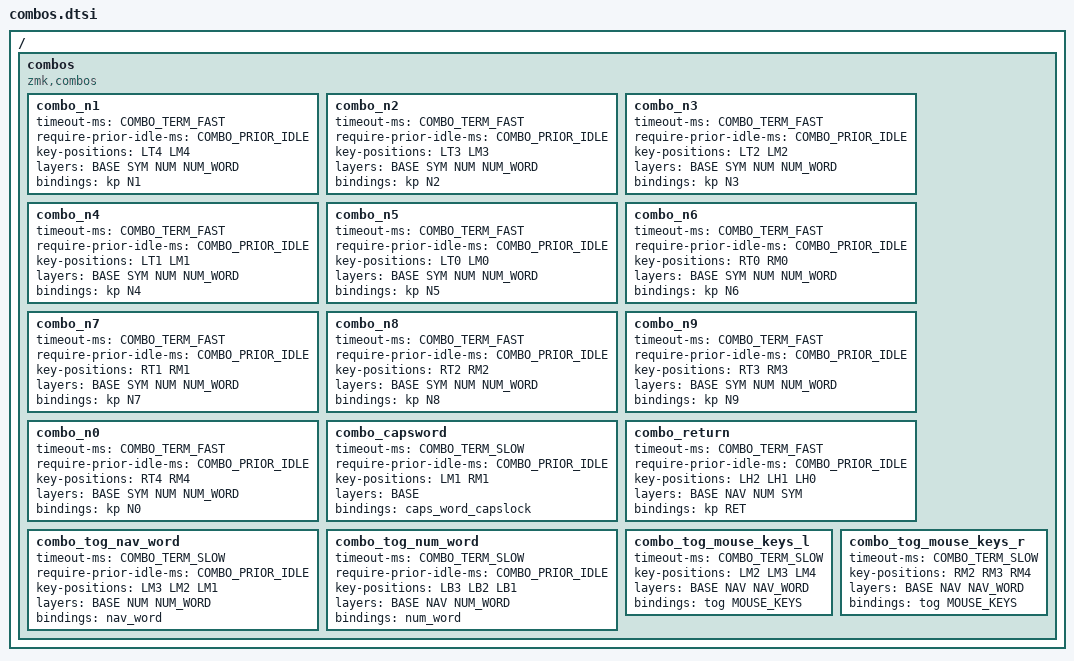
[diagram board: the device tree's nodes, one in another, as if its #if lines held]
#define COMBO_TERM_FAST 35
#define COMBO_TERM_SLOW 40
#define COMBO_TERM_SLOWER 50
#define COMBO_PRIOR_IDLE 100

// #define COMBO_TERM_FAST 18
// #define COMBO_TERM_SLOW 30

#define COMBO_IDLE_FAST 150
#define COMBO_IDLE_SLOW 50

ZMK_COMBO(esc,    &kp ESC,       LT3 LT2,     BASE NAV_WORD NAV NUM, COMBO_TERM_FAST, COMBO_IDLE_FAST)
ZMK_COMBO(cancel, &kp K_CANCEL,  LT4 LT3,     BASE NAV_WORD NAV NUM, COMBO_TERM_FAST, COMBO_IDLE_FAST)
ZMK_COMBO(ret,    &kp RETURN,    RM3 RM2,     BASE NAV NUM, COMBO_TERM_FAST, COMBO_IDLE_FAST)
// ZMK_COMBO(mouse, &smart_mouse, LT3 LT1,     DEF NAV NUM, COMBO_TERM_FAST, COMBO_IDLE_FAST)

// Combos overlapping HRMs are set up as hold-taps themselves to allow for instantaneous
// chording of mods. Custom hold-tap instances can be bootstrapped on the go using the
// 8-argument version of ZMK_COMBO defined in base.keymap.
ZMK_COMBO(tab,   &hm_l LS(LALT)TAB, LM3 LM2, BASE NAV NUM, COMBO_TERM_FAST, COMBO_IDLE_FAST)
// ZMK_COMBO(ldr,   &leader,      LM2 LM1,     BASE NAV NUM, COMBO_TERM_FAST, COMBO_IDLE_FAST, LS(LCTRL),    KEYS_R)
// ZMK_COMBO(ldrsh, &leader_sft,  LM3 LM2 LM1, BASE NAV NUM, COMBO_TERM_FAST, COMBO_IDLE_FAST, LS(LC(LALT)), KEYS_R)

ZMK_COMBO(cut,   &kp LC(X),    LB3 LB1,     BASE NAV NUM, COMBO_TERM_FAST, COMBO_IDLE_FAST)
ZMK_COMBO(copy,  &kp LC(INS),  LB3 LB2,     BASE NAV NUM, COMBO_TERM_FAST, COMBO_IDLE_FAST)
ZMK_COMBO(paste, &kp LS(INS),  LB2 LB1,     BASE NAV NUM, COMBO_TERM_FAST, COMBO_IDLE_FAST)

/* Horizontal combos - right hand */
ZMK_COMBO(bspc,  &kp BSPC,     RT1 RT2,     BASE NAV NUM, COMBO_TERM_SLOWER,  COMBO_IDLE_FAST)
ZMK_COMBO(del,   &kp DEL,      RT2 RT3,     BASE NAV NUM, COMBO_TERM_FAST,    COMBO_IDLE_FAST)

// ZMK_COMBO(lpar,  &lpar_lt,     RM1 RM2,     BASE     NUM, COMBO_TERM_FAST, COMBO_IDLE_FAST, RS(LCTRL),    KEYS_L)
// ZMK_COMBO(rpar,  &rpar_gt,     RM2 RM3,     BASE     NUM, COMBO_TERM_FAST, COMBO_IDLE_FAST, RS(LALT),     KEYS_L)
// ZMK_COMBO(lt,    &kp LT,       RM1 RM2,         NAV    , COMBO_TERM_FAST, COMBO_IDLE_FAST)
// ZMK_COMBO(gt,    &kp GT,       RM2 RM3,         NAV    , COMBO_TERM_FAST, COMBO_IDLE_FAST)
// mine
// ZMK_COMBO(lpar,  &kp LPAR,     RM1 RM2,     BASE     NUM, COMBO_TERM_FAST, COMBO_IDLE_FAST, RS(LCTRL),    KEYS_L)
// ZMK_COMBO(rpar,  &kp RPAR,     RM2 RM3,     BASE     NUM, COMBO_TERM_FAST, COMBO_IDLE_FAST, RS(LALT),     KEYS_L)

// ZMK_COMBO(lbkt,  &kp LBKT,     RB1 RB2,     BASE     NUM, COMBO_TERM_FAST, COMBO_IDLE_FAST)
// ZMK_COMBO(rbkt,  &kp RBKT,     RB2 RB3,     BASE     NUM, COMBO_TERM_FAST, COMBO_IDLE_FAST)
// ZMK_COMBO(lbrc,  &kp LBRC,     RB1 RB2,         NAV    , COMBO_TERM_FAST, COMBO_IDLE_FAST)
// ZMK_COMBO(rbrc,  &kp RBRC,     RB2 RB3,         NAV    , COMBO_TERM_FAST, COMBO_IDLE_FAST)

// ZMK_COMBO(under, &kp UNDER,    RM0 RB0,     BASE NAV NUM, COMBO_TERM_SLOW, COMBO_IDLE_SLOW)
// ZMK_COMBO(minus, &kp MINUS,    RM1 RB1,     BASE NAV NUM, COMBO_TERM_SLOW, COMBO_IDLE_SLOW)

/ {
  combos {
    compatible = "zmk,combos";

    // combo_bracket_round_l {
    //   timeout-ms = <COMBO_TERM_FAST>;
    //   require-prior-idle-ms = <COMBO_PRIOR_IDLE>;
    //   key-positions = <LM2 LM1>;
    //   layers = <BASE BASE_QWERTY SYM NUM NUM_WORD>;
    //   bindings = <&kp LPAR>;
    // };

    // combo_bracket_round_r {
    //   timeout-ms = <COMBO_TERM_FAST>;
    //   require-prior-idle-ms = <COMBO_PRIOR_IDLE>;
    //   key-positions = <RM1 RM2>;
    //   layers = <BASE BASE_QWERTY SYM NUM NUM_WORD>;
    //   bindings = <&kp RPAR>;
    // };

    // combo_bracket_square_l {
    //   timeout-ms = <COMBO_TERM_SLOW>;
    //   require-prior-idle-ms = <COMBO_PRIOR_IDLE>;
    //   key-positions = <LB2 LB1>;
    //   layers = <BASE BASE_QWERTY SYM NUM NUM_WORD>;
    //   bindings = <&kp LBKT>;
    // };

    // combo_bracket_square_r {
    //   timeout-ms = <COMBO_TERM_SLOW>;
    //   require-prior-idle-ms = <COMBO_PRIOR_IDLE>;
    //   key-positions = <RB1 RB2>;
    //   layers = <BASE BASE_QWERTY SYM NUM NUM_WORD>;
    //   bindings = <&kp RBKT>;
    // };

    // combo_bracket_curly_l {
    //   timeout-ms = <COMBO_TERM_SLOW>;
    //   require-prior-idle-ms = <COMBO_PRIOR_IDLE>;
    //   key-positions = <LT2 LT1>;
    //   layers = <BASE BASE_QWERTY SYM NUM NUM_WORD>;
    //   bindings = <&kp LBRC>;
    // };

    // combo_bracket_curly_r {
    //   timeout-ms = <COMBO_TERM_SLOW>;
    //   require-prior-idle-ms = <COMBO_PRIOR_IDLE>;
    //   key-positions = <RT2 RT1>;
    //   layers = <BASE BASE_QWERTY SYM NUM NUM_WORD>;
    //   bindings = <&kp RBRC>;
    // };

    // combo_bracket_angled_l {
    //   timeout-ms = <COMBO_TERM_SLOW>;
    //   require-prior-idle-ms = <COMBO_PRIOR_IDLE>;
    //   key-positions = <LM3 LM2>;
    //   layers = <BASE BASE_QWERTY SYM NUM NUM_WORD>;
    //   bindings = <&kp LT>;
    // };

    // combo_bracket_angled_r {
    //   timeout-ms = <COMBO_TERM_SLOW>;
    //   require-prior-idle-ms = <COMBO_PRIOR_IDLE>;
    //   key-positions = <RM3 RM2>;
    //   layers = <BASE BASE_QWERTY SYM NUM NUM_WORD>;
    //   bindings = <&kp GT>;
    // };

    // Mine
    combo_n1 {
      timeout-ms = <COMBO_TERM_FAST>;
      require-prior-idle-ms = <COMBO_PRIOR_IDLE>;
      key-positions = <LT4 LM4>;
      layers = <BASE SYM NUM NUM_WORD>;
      // layers = <BASE NAV SYM ADJ>;
      bindings = <&kp N1>;
    };

    combo_n2 {
      timeout-ms = <COMBO_TERM_FAST>;
      require-prior-idle-ms = <COMBO_PRIOR_IDLE>;
      key-positions = <LT3 LM3>;
      layers = <BASE SYM NUM NUM_WORD>;
      // layers = <BASE NAV SYM ADJ>;
      bindings = <&kp N2>;
    };

    combo_n3 {
      timeout-ms = <COMBO_TERM_FAST>;
      require-prior-idle-ms = <COMBO_PRIOR_IDLE>;
      key-positions = <LT2 LM2>;
      layers = <BASE SYM NUM NUM_WORD>;
      // layers = <BASE NAV SYM ADJ>;
      bindings = <&kp N3>;
    };

    combo_n4 {
      timeout-ms = <COMBO_TERM_FAST>;
      require-prior-idle-ms = <COMBO_PRIOR_IDLE>;
      key-positions = <LT1 LM1>;
      layers = <BASE SYM NUM NUM_WORD>;
      // layers = <BASE NAV SYM ADJ>;
      bindings = <&kp N4>;
    };

    combo_n5 {
      timeout-ms = <COMBO_TERM_FAST>;
      require-prior-idle-ms = <COMBO_PRIOR_IDLE>;
      key-positions = <LT0 LM0>;
      layers = <BASE SYM NUM NUM_WORD>;
      // layers = <BASE NAV SYM ADJ>;
      bindings = <&kp N5>;
    };

    combo_n6 {
      timeout-ms = <COMBO_TERM_FAST>;
      require-prior-idle-ms = <COMBO_PRIOR_IDLE>;
      key-positions = <RT0 RM0>;
      layers = <BASE SYM NUM NUM_WORD>;
      // layers = <BASE NAV SYM ADJ>;
      bindings = <&kp N6>;
    };

    combo_n7 {
      timeout-ms = <COMBO_TERM_FAST>;
      require-prior-idle-ms = <COMBO_PRIOR_IDLE>;
      key-positions = <RT1 RM1>;
      layers = <BASE SYM NUM NUM_WORD>;
      // layers = <BASE NAV SYM ADJ>;
      bindings = <&kp N7>;
    };

    combo_n8 {
      timeout-ms = <COMBO_TERM_FAST>;
      require-prior-idle-ms = <COMBO_PRIOR_IDLE>;
      key-positions = <RT2 RM2>;
      layers = <BASE SYM NUM NUM_WORD>;
      // layers = <BASE NAV SYM ADJ>;
      bindings = <&kp N8>;
    };

    combo_n9 {
      timeout-ms = <COMBO_TERM_FAST>;
      require-prior-idle-ms = <COMBO_PRIOR_IDLE>;
      key-positions = <RT3 RM3>;
      layers = <BASE SYM NUM NUM_WORD>;
      // layers = <BASE NAV SYM ADJ>;
      bindings = <&kp N9>;
    };

    combo_n0 {
      timeout-ms = <COMBO_TERM_FAST>;
      require-prior-idle-ms = <COMBO_PRIOR_IDLE>;
      key-positions = <RT4 RM4>;
      layers = <BASE SYM NUM NUM_WORD>;
      // layers = <BASE NAV SYM ADJ>;
      bindings = <&kp N0>;
    };
    // End mine

    // combo_bracket_v_round_l {
    //   timeout-ms = <COMBO_TERM_FAST>;
    //   require-prior-idle-ms = <COMBO_PRIOR_IDLE>;
    //   key-positions = <LT1 LM1>;
    //   layers = <BASE SYM NUM NUM_WORD>;
    //   // layers = <BASE NAV SYM ADJ>;
    //   bindings = <&kp LPAR>;
    // };
    //
    // combo_bracket_v_round_r {
    //   timeout-ms = <COMBO_TERM_FAST>;
    //   require-prior-idle-ms = <COMBO_PRIOR_IDLE>;
    //   key-positions = <RT1 RM1>;
    //   // layers = <BASE BASE_QWERTY SYM NUM NUM_WORD>;
    //   // layers = <BASE NAV SYM ADJ>;
    //   layers = <BASE SYM NUM NUM_WORD>;
    //   bindings = <&kp RPAR>;
    // };
    //
    // combo_bracket_v_square_l {
    //   timeout-ms = <COMBO_TERM_SLOW>;
    //   require-prior-idle-ms = <COMBO_PRIOR_IDLE>;
    //   key-positions = <LT2 LM2>;
    //   // layers = <BASE BASE_QWERTY SYM NUM NUM_WORD>;
    //   layers = <BASE SYM NUM NUM_WORD>;
    //   // layers = <BASE NAV SYM ADJ>;
    //   bindings = <&kp LBKT>;
    // };
    //
    // combo_bracket_v_square_r {
    //   timeout-ms = <COMBO_TERM_SLOW>;
    //   require-prior-idle-ms = <COMBO_PRIOR_IDLE>;
    //   key-positions = <RT2 RM2>;
    //   // layers = <BASE BASE_QWERTY SYM NUM NUM_WORD>;
    //   layers = <BASE SYM NUM NUM_WORD>;
    //   // layers = <BASE NAV SYM ADJ>;
    //   bindings = <&kp RBKT>;
    // };
    //
    // combo_bracket_v_curly_l {
    //   timeout-ms = <COMBO_TERM_SLOW>;
    //   require-prior-idle-ms = <COMBO_PRIOR_IDLE>;
    //   key-positions = <LT3 LM3>;
    //   // layers = <BASE BASE_QWERTY SYM NUM NUM_WORD>;
    //   layers = <BASE SYM NUM NUM_WORD>;
    //   // layers = <BASE NAV SYM ADJ>;
    //   bindings = <&kp LBRC>;
    // };
    //
    // combo_bracket_v_curly_r {
    //   timeout-ms = <COMBO_TERM_SLOW>;
    //   require-prior-idle-ms = <COMBO_PRIOR_IDLE>;
    //   key-positions = <RT3 RM3>;
    //   // layers = <BASE BASE_QWERTY SYM NUM NUM_WORD>;
    //   layers = <BASE SYM NUM NUM_WORD>;
    //   // layers = <BASE NAV SYM ADJ>;
    //   bindings = <&kp RBRC>;
    // };
    //
    // combo_bracket_v_angled_l {
    //   timeout-ms = <COMBO_TERM_SLOW>;
    //   require-prior-idle-ms = <COMBO_PRIOR_IDLE>;
    //   key-positions = <LM1 LB1>;
    //   // layers = <BASE BASE_QWERTY SYM NUM NUM_WORD>;
    //   layers = <BASE SYM NUM NUM_WORD>;
    //   // layers = <BASE NAV SYM ADJ>;
    //   bindings = <&kp LT>;
    // };
    //
    // combo_bracket_v_angled_r {
    //   timeout-ms = <COMBO_TERM_SLOW>;
    //   require-prior-idle-ms = <COMBO_PRIOR_IDLE>;
    //   key-positions = <RM1 RB1>;
    //   // layers = <BASE BASE_QWERTY SYM NUM NUM_WORD>;
    //   layers = <BASE SYM NUM NUM_WORD>;
    //   // layers = <BASE NAV SYM ADJ>;
    //   bindings = <&kp GT>;
    // };

    combo_capsword {
      timeout-ms = <COMBO_TERM_SLOW>;
      require-prior-idle-ms = <COMBO_PRIOR_IDLE>;
      key-positions = <LM1 RM1>;
      // layers = <BASE BASE_QWERTY>;
      layers = <BASE>;
      // layers = <BASE NAV SYM ADJ>;

#ifdef HAS_CAPSLOCK
      bindings = <&caps_word_capslock >;
#else
      bindings = <&caps_word>;
#endif
    };

    combo_return {
      timeout-ms = <COMBO_TERM_FAST>;
      require-prior-idle-ms = <COMBO_PRIOR_IDLE>;
      key-positions = <LH2 LH1 LH0>;
      // layers = <BASE BASE_QWERTY NAV NUM SYM>;
      layers = <BASE NAV NUM SYM>;
      // layers = <BASE NAV SYM ADJ>;
      bindings = <&kp RET>;
    };

    // combo_bspc {
    //   timeout-ms = <COMBO_TERM_FAST>;
    //   require-prior-idle-ms = <COMBO_PRIOR_IDLE>;
    //   key-positions = <LH1 LH0>;
    //   // layers = <BASE BASE_QWERTY NAV NUM SYM>;
    //   layers = <BASE NAV NUM SYM>;
    //   // layers = <BASE NAV SYM ADJ>;
    //   bindings = <&kp BSPC>;
    // };

    // combo_grave {
    //   timeout-ms = <COMBO_TERM_SLOW>;
    //   require-prior-idle-ms = <COMBO_PRIOR_IDLE>;
    //   key-positions = <RM3 RM4>;
    //   layers = <>;
    //   bindings = <&kp GRAVE>;
    // };

    // combo_md_code_block {
    //   timeout-ms = <COMBO_TERM_SLOW>;
    //   require-prior-idle-ms = <COMBO_PRIOR_IDLE>;
    //   key-positions = <RM2 RM3 RM4>;
    //   layers = <>;
    //   bindings = <&m_type_md_code_block>;
    // };

    combo_tog_nav_word {
      timeout-ms = <COMBO_TERM_SLOW>;
      require-prior-idle-ms = <COMBO_PRIOR_IDLE>;
      key-positions = <LM3 LM2 LM1>;
      // layers = <BASE BASE_QWERTY NUM NUM_WORD>;
      layers = <BASE NUM NUM_WORD>;
      // layers = <BASE NAV SYM ADJ>;

      #ifdef HAS_UROB
        bindings = <&nav_word>;
      #else
        bindings = <&tog NAV_WORD>;
      #endif

    };

    combo_tog_num_word {
      timeout-ms = <COMBO_TERM_SLOW>;
      require-prior-idle-ms = <COMBO_PRIOR_IDLE>;
      key-positions = <LB3 LB2 LB1>;
      // layers = <BASE BASE_QWERTY NAV NAV_WORD>;
      layers = <BASE NAV NUM_WORD>;
      // layers = <BASE NAV SYM ADJ>;

      #ifdef HAS_UROB
        bindings = <&num_word>;
      #else
        bindings = <&tog NUM_WORD>;
      #endif

    };

#ifdef HAS_PS2
    // combo_tog_mouse_settings_l {
    //   timeout-ms = <COMBO_TERM_SLOW>;
    //   // require-prior-idle-ms = <COMBO_PRIOR_IDLE>;
    //   key-positions = <LT2 LT3 LT4>;
    //   layers = <BASE BASE_QWERTY NAV NAV_WORD MOUSE_KEYS>;
    //   bindings = <&tog MOUSE_SET>;
    // };

    // combo_tog_mouse_settings_r {
    //   timeout-ms = <COMBO_TERM_SLOW>;
    //   // require-prior-idle-ms = <COMBO_PRIOR_IDLE>;
    //   key-positions = <RT2 RT3 RT4>;
    //   layers = <BASE BASE_QWERTY NAV NAV_WORD MOUSE_KEYS>;
    //   bindings = <&tog MOUSE_SET>;
    // };
#endif

#ifdef HAS_MOUSE_KEYS
    combo_tog_mouse_keys_l {
      timeout-ms = <COMBO_TERM_SLOW>;
      // require-prior-idle-ms = <COMBO_PRIOR_IDLE>;
      key-positions = <LM2 LM3 LM4>;
      // layers = <BASE BASE_QWERTY NAV NAV_WORD MOUSE_KEYS>;
      layers = <BASE NAV NAV_WORD>;
      // layers = <BASE NAV SYM ADJ>;
      bindings = <&tog MOUSE_KEYS>;
    };

    combo_tog_mouse_keys_r {
      timeout-ms = <COMBO_TERM_SLOW>;
      // require-prior-idle-ms = <COMBO_PRIOR_IDLE>;
      key-positions = <RM2 RM3 RM4>;
      layers = <BASE NAV NAV_WORD>;
      // layers = <BASE NAV SYM ADJ>;
      bindings = <&tog MOUSE_KEYS>;
    };
#endif

  };
};
